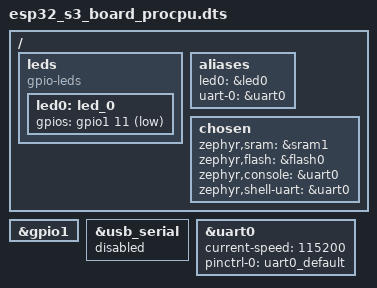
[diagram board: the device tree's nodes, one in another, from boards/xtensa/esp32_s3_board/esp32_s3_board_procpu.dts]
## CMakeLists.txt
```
# SPDX-License-Identifier: Apache-2.0

cmake_minimum_required(VERSION 3.28.0)
set(BOARD_ROOT ${CMAKE_CURRENT_SOURCE_DIR})
find_package(Zephyr REQUIRED HINTS $ENV{ZEPHYR_BASE})
project(03_hello_world)

target_sources(app PRIVATE src/main.c)
```

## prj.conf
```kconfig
# nothing here
# CONFIG_LOG=y
# CONFIG_LOG_DEFAULT_LEVEL=3
```

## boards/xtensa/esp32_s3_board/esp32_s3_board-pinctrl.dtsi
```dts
#include <zephyr/dt-bindings/pinctrl/esp32s3-pinctrl.h>

&pinctrl {
    uart0_default: uart0_default {
        group1 {
            pinmux = <UART0_TX_GPIO43>;
            output-high;
        };
        group2 {
            pinmux = <UART0_RX_GPIO44>;
            bias-pull-up;
        };
    };
};
```

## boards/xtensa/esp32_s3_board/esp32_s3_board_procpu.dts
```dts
/dts-v1/;

#include <espressif/esp32s3/esp32s3_wroom_n8r8.dtsi>
#include <espressif/partitions_0x0_amp.dtsi>
#include "esp32_s3_board-pinctrl.dtsi"

/* root device tree*/
// hardware object nood
// container nood
// leds/led_0 -> led0

/ {
    leds {
        compatible = "gpio-leds";
        led0: led_0 {
            gpios = <&gpio1 11 GPIO_ACTIVE_LOW>;
        };
    };

    aliases {
        led0 = &led0;
        uart-0 = &uart0;
    };

    chosen {
        zephyr,sram = &sram1;
        zephyr,flash = &flash0;  
        zephyr,console = &uart0;
		zephyr,shell-uart = &uart0;        
    };

};

&gpio1 {
    status = "okay";
};

&usb_serial {
	status = "disabled";
};

&uart0 {
	status = "okay";
	current-speed = <115200>;
	pinctrl-0 = <&uart0_default>;
	pinctrl-names = "default";
};

/* esp32 clock is done defult
&clock {
    clocks = <&fast-clk-src>;
    status = "okay";
};
*/

/* power is done defult
&pwr {

};
*/
```

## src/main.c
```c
/*
 * Copyright (c) 2012-2014 Wind River Systems, Inc.
 *
 * SPDX-License-Identifier: Apache-2.0
 */

#include <stdio.h>
#include <zephyr/kernel.h>

int main(void)
{
	printk("Hello World from Zephyr!\n");

#if defined(CONFIG_LOG)
    printk("CONFIG_LOG is enabled (level=%d)\n", CONFIG_LOG_DEFAULT_LEVEL);
#else
    printk("CONFIG_LOG is disabled\n");
#endif

	return 0;
}
```
